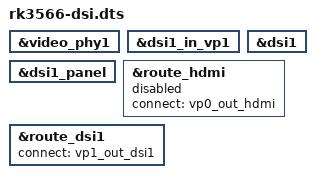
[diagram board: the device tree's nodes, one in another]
/dts-v1/;
/plugin/;

/ {
	
	fragment@0 {
		target = <&video_phy1>;

		__overlay__ {
			
			status = "okay";
		};
	};
	
	fragment@1 {
		target = <&dsi1_in_vp1>;

		__overlay__ {
			
			status = "okay";			
		};
	};
		
	fragment@2 {
		target = <&dsi1>;

		__overlay__ {
			
			status = "okay";			
		};
	};
	
	fragment@3 {
		target = <&dsi1_panel>;

		__overlay__ {
			
			status = "okay";			
		};
	};
	
	fragment@4 {
		target = <&route_hdmi>;

		__overlay__ {
			
			status = "disabled";
			connect = <&vp0_out_hdmi>;             		
		};
	};
	
	fragment@5 {
		target = <&route_dsi1>;

		__overlay__ {
			
			status = "okay";
			connect = <&vp1_out_dsi1>;             		
		};
	};
	
};
